# MGM260PD32VNN register map
Vendor: Silicon Labs; Series: EFR32; File version: 2
Registers are 32-bit, read-write, reset 0x0 unless marked. A register's access mark holds for its fields unless they carry their own. Offsets are from the block's base; [hi:lo] are bit positions; {n}, {i} and the like mark numbered series.

## SEMAILBOX_NS_HOST — SEMAILBOX_NS_HOST Registers
Base 0x5C000000
Same registers: SEMAILBOX_S_HOST 0x4C000000
0x00 FIFO — A write access to any address in this area will be mapped to the TX FIFO (only for the payload). A read access to any address in this area will be mapped to the RX FIFO (only for the payload). Using an address range (16 x 32-bit) rather than one single address mapped to the FIFO allows using incremental bursts.
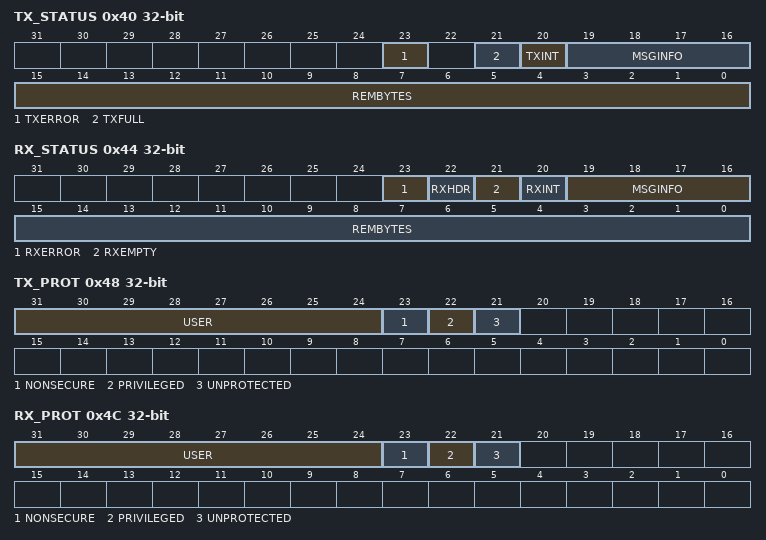
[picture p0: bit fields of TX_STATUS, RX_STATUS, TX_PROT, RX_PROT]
0x40 TX_STATUS ro
  [23] TXERROR, [21] TXFULL, [20] TXINT, [19:16] MSGINFO, [15:0] REMBYTES
0x44 RX_STATUS ro
  [23] RXERROR, [22] RXHDR, [21] RXEMPTY, [20] RXINT, [19:16] MSGINFO, [15:0] REMBYTES
0x48 TX_PROT ro — TX Protection register.
  [31:24] USER, [23] NONSECURE, [22] PRIVILEGED, [21] UNPROTECTED
0x4C RX_PROT ro — RX Protection register.
  [31:24] USER, [23] NONSECURE, [22] PRIVILEGED, [21] UNPROTECTED
0x50 TX_HEADER wo — A write access to this register will be mapped to the TX FIFO (only for header).
  [31:0] TXHEADER
0x54 RX_HEADER ro — A read access to this register will be mapped to the RX FIFO (only for the header).
  [31:0] RXHEADER
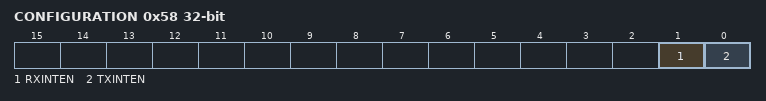
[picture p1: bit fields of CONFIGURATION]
0x58 CONFIGURATION
  [1] RXINTEN, [0] TXINTEN

## SMU_NS_CFGNS — SMU_NS_CFGNS Registers
Base 0x5400C000
Same registers: SMU_S_CFGNS 0x4400C000
0x04 NSSTATUS ro
  [0] SMUNSLOCK
    0=UNLOCKED; 1=LOCKED
0x08 NSLOCK wo
  [23:0] SMUNSLOCKKEY
    0xACCE55=UNLOCK (Unlocks Registers)
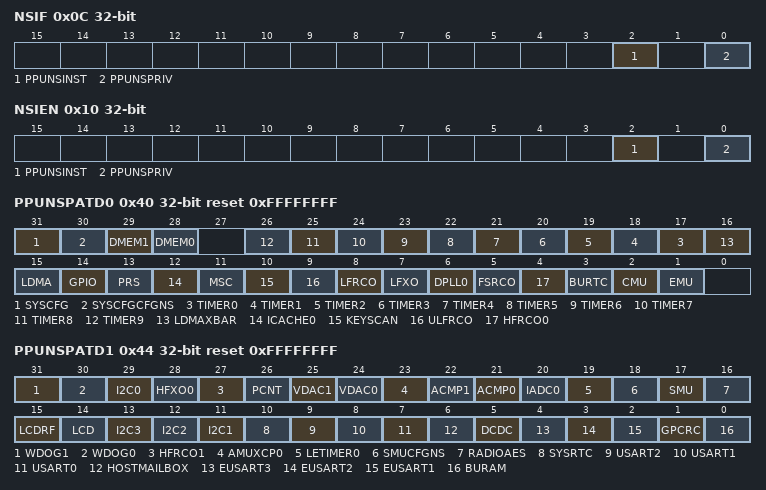
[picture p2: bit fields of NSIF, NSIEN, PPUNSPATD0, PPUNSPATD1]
0x0C NSIF
  [2] PPUNSINST — PPUNS Instruction Interrupt Flag
  [0] PPUNSPRIV — PPUNS Privilege Interrupt Flag
0x10 NSIEN
  [2] PPUNSINST — PPUNS Instruction Interrupt Enable
  [0] PPUNSPRIV — PPUNS Privilege Interrupt Enable
0x40 PPUNSPATD0 reset 0xFFFFFFFF — Set peripheral bits to 1 to mark as privileged access only
  [31] SYSCFG — SYSCFG Privileged Access
  [30] SYSCFGCFGNS — SYSCFGCFGNS Privileged Access
  [29] DMEM1 — DMEM1 Privileged Access
  [28] DMEM0 — DMEM0 Privileged Access
  [n+17] TIMER{n} (n=0..9) — TIMER{n} Privileged Access
  [16] LDMAXBAR — LDMAXBAR Privileged Access
  [15] LDMA — LDMA Privileged Access
  [14] GPIO — GPIO Privileged Access
  [13] PRS — PRS Privileged Access
  [12] ICACHE0 — ICACHE0 Privileged Access
  [11] MSC — MSC Privileged Access
  [10] KEYSCAN — KEYSCAN Privileged Access
  [9] ULFRCO — ULFRCO Privileged Access
  [8] LFRCO — LFRCO Privileged Access
  [7] LFXO — LFXO Privileged Access
  [6] DPLL0 — DPLL0 Privileged Access
  [5] FSRCO — FSRCO Privileged Access
  [4] HFRCO0 — HFRCO0 Privileged Access
  [3] BURTC — BURTC Privileged Access
  [2] CMU — CMU Privileged Access
  [1] EMU — EMU Privileged Access
0x44 PPUNSPATD1 reset 0xFFFFFFFF — Set peripheral bits to 1 to mark as privileged access only
  [31] WDOG1 — WDOG1 Privileged Access
  [30] WDOG0 — WDOG0 Privileged Access
  [29] I2C0 — I2C0 Privileged Access
  [28] HFXO0 — HFXO0 Privileged Access
  [27] HFRCO1 — HFRCO1 Privileged Access
  [26] PCNT — PCNT Privileged Access
  [25] VDAC1 — VDAC1 Privileged Access
  [24] VDAC0 — VDAC0 Privileged Access
  [23] AMUXCP0 — AMUXCP0 Privileged Access
  [22] ACMP1 — ACMP1 Privileged Access
  [21] ACMP0 — ACMP0 Privileged Access
  [20] IADC0 — IADC0 Privileged Access
  [19] LETIMER0 — LETIMER0 Privileged Access
  [18] SMUCFGNS — SMUCFGNS Privileged Access
  [17] SMU — SMU Privileged Access
  [16] RADIOAES — RADIOAES Privileged Access
  [15] LCDRF — LCDRF Privileged Access
  [14] LCD — LCD Privileged Access
  [13] I2C3 — I2C3 Privileged Access
  [12] I2C2 — I2C2 Privileged Access
  [11] I2C1 — I2C1 Privileged Access
  [10] SYSRTC — SYSRTC Privileged Access
  [9] USART2 — USART2 Privileged Access
  [8] USART1 — USART1 Privileged Access
  [7] USART0 — USART0 Privileged Access
  [6] HOSTMAILBOX — HOSTMAILBOX Privileged Access
  [5] DCDC — DCDC Privileged Access
  [4] EUSART3 — EUSART3 Privileged Access
  [3] EUSART2 — EUSART2 Privileged Access
  [2] EUSART1 — EUSART1 Privileged Access
  [1] GPCRC — GPCRC Privileged Access
  [0] BURAM — BURAM Privileged Access
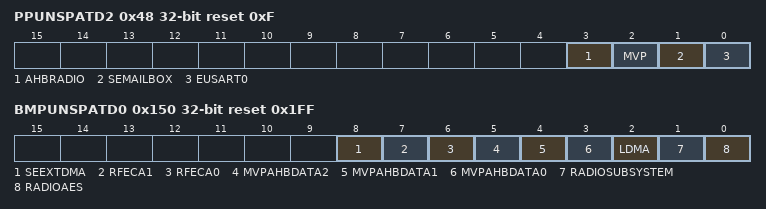
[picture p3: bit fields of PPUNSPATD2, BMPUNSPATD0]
0x48 PPUNSPATD2 reset 0xF — Set peripheral bits to 1 to mark as privileged access only
  [3] AHBRADIO — AHBRADIO Privileged Access
  [2] MVP — MVP Privileged Access
  [1] SEMAILBOX — SEMAILBOX Privileged Access
  [0] EUSART0 — EUSART0 Privileged Access
0x140 PPUNSFS ro
  [7:0] PPUFSPERIPHID — Peripheral I
0x150 BMPUNSPATD0 reset 0x1FF
  [8] SEEXTDMA — SEEXTDMA Privileged Mode
  [7] RFECA1 — RFECA1 Privileged Mode
  [6] RFECA0 — RFECA0 Privileged Mode
  [5] MVPAHBDATA2 — MVPAHBDATA2 Privileged Mode
  [4] MVPAHBDATA1 — MVPAHBDATA1 Privileged Mode
  [3] MVPAHBDATA0 — MVPAHBDATA0 Privileged Mode
  [2] LDMA — LDMA Privileged Mode
  [1] RADIOSUBSYSTEM — RADIOSUBSYSTEM Privileged Mode
  [0] RADIOAES — RADIOAES Privileged Mode
